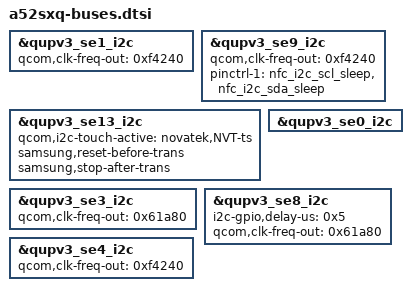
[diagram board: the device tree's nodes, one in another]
// SPDX-License-Identifier: GPL-2.0
/*
 * a52sxq board description for the Qualcomm 6.12 yupik base: buses
 * GENERATED by tools/gen.py from the phone's stock dtbo (5.4 bindings, values verbatim).
 * Do not edit: hand-written 6.12 changes live in a52sxq-bsp612-fixups.dtsi.
 */

&qupv3_se1_i2c {
	#address-cells = <0x1>;
	#size-cells = <0x0>;
	status = "ok";
	qcom,clk-freq-out = <0xf4240>;
};

&qupv3_se9_i2c {
	status = "okay";
	qcom,clk-freq-out = <0xf4240>;
	#address-cells = <0x1>;
	#size-cells = <0x0>;
	pinctrl-1 = <&nfc_i2c_scl_sleep &nfc_i2c_sda_sleep>;
};

&qupv3_se13_i2c {
	#address-cells = <0x1>;
	#size-cells = <0x0>;
	status = "ok";
	qcom,i2c-touch-active = "novatek,NVT-ts";
	samsung,reset-before-trans;
	samsung,stop-after-trans;
};

&qupv3_se0_i2c {
	#address-cells = <0x1>;
	#size-cells = <0x0>;
	status = "okay";
};

&qupv3_se3_i2c {
	#address-cells = <0x1>;
	#size-cells = <0x0>;
	status = "ok";
	qcom,clk-freq-out = <0x61a80>;
};

&qupv3_se8_i2c {
	i2c-gpio,delay-us = <0x5>;
	#address-cells = <0x1>;
	#size-cells = <0x0>;
	status = "okay";
	qcom,clk-freq-out = <0x61a80>;
};

&qupv3_se4_i2c {
	status = "ok";
	qcom,clk-freq-out = <0xf4240>;
};

